VERSION ""

NS_ :

BS_:

BU_: ECU Motor PowerAux Solar MotorController

BO_ 100 AuxBatteryStatus: 3 PowerAux
 SG_ aux_voltage : 0|16@1+ (1,0) [0|0] "mV" Vector__XXX
 SG_ percent_full : 16|8@1+ (1,0) [0|0] "hex%" Vector__XXX

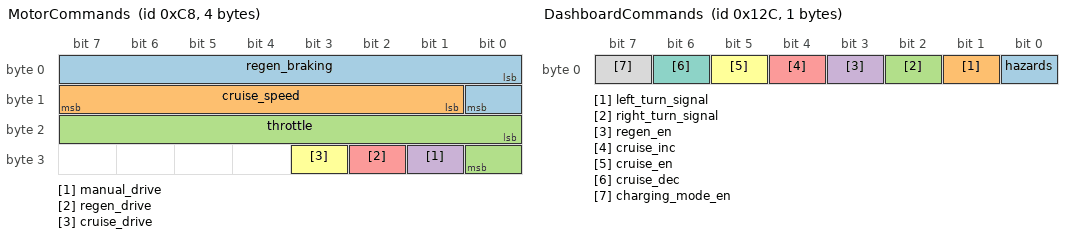
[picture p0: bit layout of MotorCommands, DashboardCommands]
BO_ 200 MotorCommands: 4 ECU
 SG_ regen_braking : 0|9@1+ (1,0) [0|256] "" Vector__XXX
 SG_ cruise_speed : 9|7@1+ (1,0) [0|0] "mph" Vector__XXX
 SG_ throttle : 16|9@1+ (1,0) [0|256] "" Vector__XXX
 SG_ manual_drive : 25|1@1+ (1,0) [0|0] "" Vector__XXX
 SG_ regen_drive : 26|1@1+ (1,0) [0|0] "" Vector__XXX
 SG_ cruise_drive : 27|1@1+ (1,0) [0|0] "" Vector__XXX

BO_ 300 DashboardCommands: 1 ECU
 SG_ hazards : 0|1@1+ (1,0) [0|0] "" Vector__XXX
 SG_ left_turn_signal : 1|1@1+ (1,0) [0|0] "" Vector__XXX
 SG_ right_turn_signal : 2|1@1+ (1,0) [0|0] "" Vector__XXX
 SG_ regen_en : 3|1@1+ (1,0) [0|0] "" Vector__XXX
 SG_ cruise_inc : 4|1@1+ (1,0) [0|0] "" Vector__XXX
 SG_ cruise_en : 5|1@1+ (1,0) [0|0] "" Vector__XXX
 SG_ cruise_dec : 6|1@1+ (1,0) [0|0] "" Vector__XXX
 SG_ charging_mode_en : 7|1@1+ (1,0) [0|0] "" Vector__XXX

BO_ 400 Heartbeat: 1 Vector__XXX
 SG_ source : 0|8@1+ (1,0) [0|0] "" Vector__XXX

BO_ 500 PedalStatus: 3 Vector__XXX
 SG_ throttle_pedal : 0|12@1+ (1,0) [0|0] "" Vector__XXX
 SG_ brake_pedal : 12|12@1+ (1,0) [0|0] "" Vector__XXX

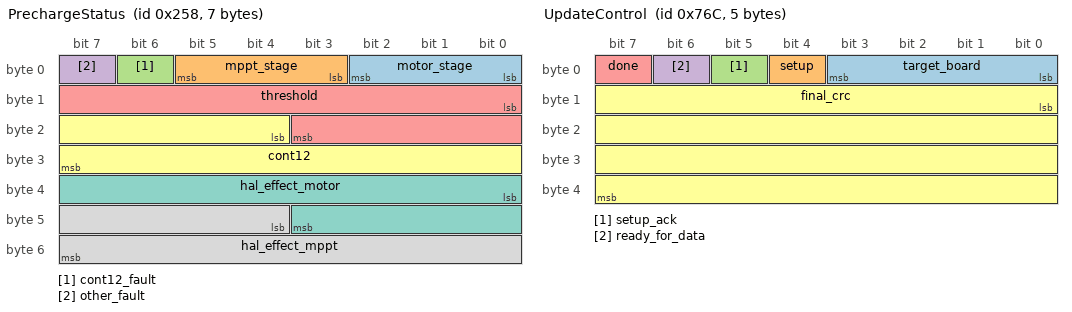
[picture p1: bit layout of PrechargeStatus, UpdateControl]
BO_ 600 PrechargeStatus: 7 Vector__XXX
 SG_ motor_stage : 0|3@1+ (1,0) [0|0] "" Vector__XXX
 SG_ mppt_stage : 3|3@1+ (1,0) [0|0] "" Vector__XXX
 SG_ cont12_fault : 6|1@1+ (1,0) [0|0] "" Vector__XXX
 SG_ other_fault : 7|1@1+ (1,0) [0|0] "" Vector__XXX
 SG_ threshold : 8|12@1+ (1,0) [0|0] "" Vector__XXX
 SG_ cont12 : 20|12@1+ (1,0) [0|0] "" Vector__XXX
 SG_ hal_effect_motor : 32|12@1+ (1,0) [0|0] "" Vector__XXX
 SG_ hal_effect_mppt : 44|12@1+ (1,0) [0|0] "" Vector__XXX

BO_ 700 Contactor12Error: 1 Vector__XXX
 SG_ cont12_went_low : 0|1@1+ (1,0) [0|0] "" Vector__XXX

BO_ 1900 UpdateControl: 5 Vector__XXX
 SG_ target_board : 0|4@1+ (1,0) [0|0] "" Vector__XXX
 SG_ setup : 4|1@1+ (1,0) [0|0] "" Vector__XXX
 SG_ setup_ack : 5|1@1+ (1,0) [0|0] "" Vector__XXX
 SG_ ready_for_data : 6|1@1+ (1,0) [0|0] "" Vector__XXX
 SG_ done : 7|1@1+ (1,0) [0|0] "" Vector__XXX
 SG_ final_crc : 8|32@1+ (1,0) [0|0] "" Vector__XXX

BO_ 2000 UpdateData: 64 Vector__XXX
 SG_ data : 0|512@1+ (1,0) [0|0] "" Vector__XXX

BO_ 800 OdometryData: 4 Vector__XXX
 SG_ distance : 0|32@1+ (1,0) [0|0] "" Vector__XXX

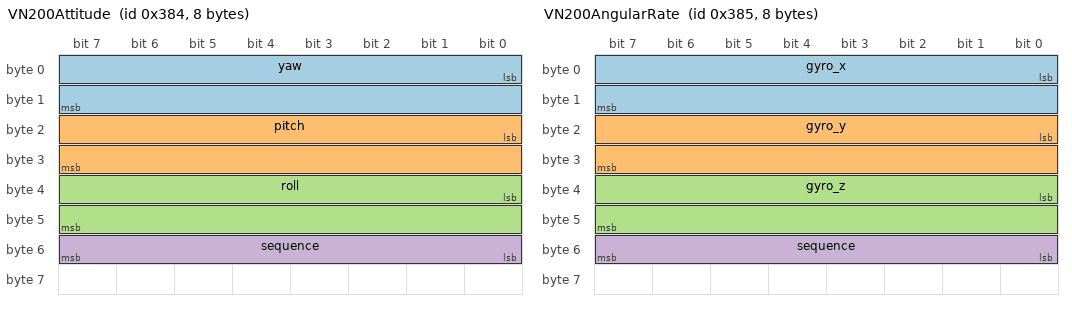
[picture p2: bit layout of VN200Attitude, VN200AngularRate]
BO_ 900 VN200Attitude: 8 Vector__XXX
 SG_ yaw : 0|16@1- (0.01,0) [0|0] "" Vector__XXX
 SG_ pitch : 16|16@1- (0.01,0) [0|0] "" Vector__XXX
 SG_ roll : 32|16@1- (0.01,0) [0|0] "" Vector__XXX
 SG_ sequence : 48|8@1+ (1,0) [0|0] "" Vector__XXX

BO_ 901 VN200AngularRate: 8 Vector__XXX
 SG_ gyro_x : 0|16@1- (0.001,0) [0|0] "" Vector__XXX
 SG_ gyro_y : 16|16@1- (0.001,0) [0|0] "" Vector__XXX
 SG_ gyro_z : 32|16@1- (0.001,0) [0|0] "" Vector__XXX
 SG_ sequence : 48|8@1+ (1,0) [0|0] "" Vector__XXX

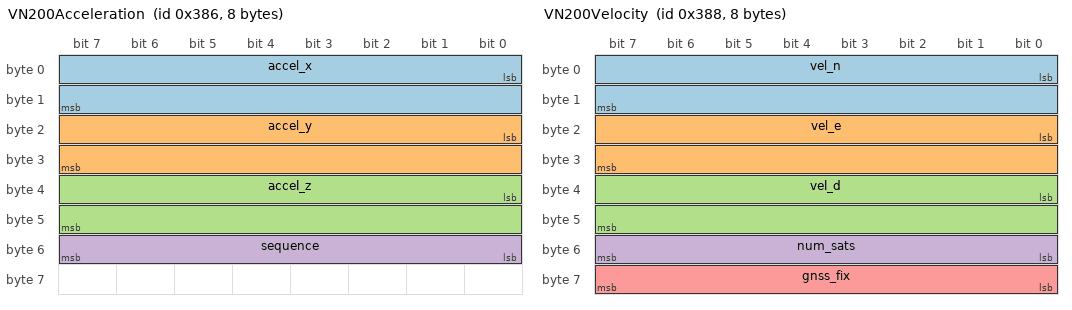
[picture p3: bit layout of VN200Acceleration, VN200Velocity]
BO_ 902 VN200Acceleration: 8 Vector__XXX
 SG_ accel_x : 0|16@1- (0.01,0) [0|0] "" Vector__XXX
 SG_ accel_y : 16|16@1- (0.01,0) [0|0] "" Vector__XXX
 SG_ accel_z : 32|16@1- (0.01,0) [0|0] "" Vector__XXX
 SG_ sequence : 48|8@1+ (1,0) [0|0] "" Vector__XXX

BO_ 903 VN200Position: 8 Vector__XXX
 SG_ latitude : 0|32@1- (1E-07,0) [0|0] "" Vector__XXX
 SG_ longitude : 32|32@1- (1E-07,0) [0|0] "" Vector__XXX

BO_ 904 VN200Velocity: 8 Vector__XXX
 SG_ vel_n : 0|16@1- (0.01,0) [0|0] "" Vector__XXX
 SG_ vel_e : 16|16@1- (0.01,0) [0|0] "" Vector__XXX
 SG_ vel_d : 32|16@1- (0.01,0) [0|0] "" Vector__XXX
 SG_ num_sats : 48|8@1+ (1,0) [0|0] "" Vector__XXX
 SG_ gnss_fix : 56|8@1+ (1,0) [0|0] "" Vector__XXX

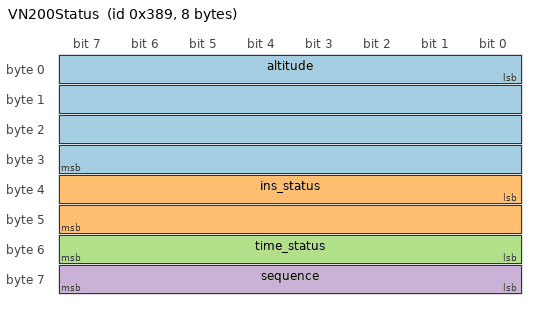
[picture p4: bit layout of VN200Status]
BO_ 905 VN200Status: 8 Vector__XXX
 SG_ altitude : 0|32@1- (0.01,0) [0|0] "" Vector__XXX
 SG_ ins_status : 32|16@1+ (1,0) [0|0] "" Vector__XXX
 SG_ time_status : 48|8@1+ (1,0) [0|0] "" Vector__XXX
 SG_ sequence : 56|8@1+ (1,0) [0|0] "" Vector__XXX

CM_ SG_ 700 cont12_went_low "fault";
BA_DEF_  "BusType" STRING ;
BA_DEF_DEF_  "BusType" "CAN";
